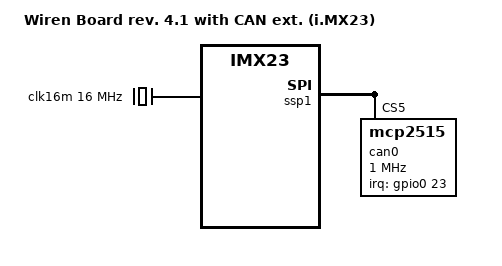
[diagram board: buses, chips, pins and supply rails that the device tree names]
/*
 * Copyright 2012 Freescale Semiconductor, Inc.
 *
 * Author: Fabio Estevam <fabio.estevam@freescale.com>
 *
 * The code contained herein is licensed under the GNU General Public
 * License. You may obtain a copy of the GNU General Public License
 * Version 2 or later at the following locations:
 *
 * http://www.opensource.org/licenses/gpl-license.html
 * http://www.gnu.org/copyleft/gpl.html
 */

#include "imx23-wirenboard41.dts"

/ {

	model = "Wiren Board rev. 4.1 with CAN ext. (i.MX23)";

	compatible = "contactless,imx23-wirenboard41-can", "contactless,imx23-wirenboard41", "contactless,imx23-wirenboard32", "olimex,imx23-olinuxino", "fsl,imx23";

    clk16m: oscillator {
         compatible = "fixed-clock";
         #clock-cells = <0>;
         clock-frequency  = <16000000>;
         clock-output-names = "clk16m";
    };


	apb@80000000 {
		apbh@80000000 {
			ssp1: ssp@80034000 {

				spidev@5 {
					status = "disabled";
				};

				can0: mcp2515@5 {
					compatible = "mcp2515";
					reg = <5>;
					spi-max-frequency = <1000000>;

					clocks = <&clk16m>;

					interrupt-parent = <&gpio0>;
					interrupts = <23 0>;  /* gpio 23, IRQ at EXT */
				};


			};
		};
	};

};
